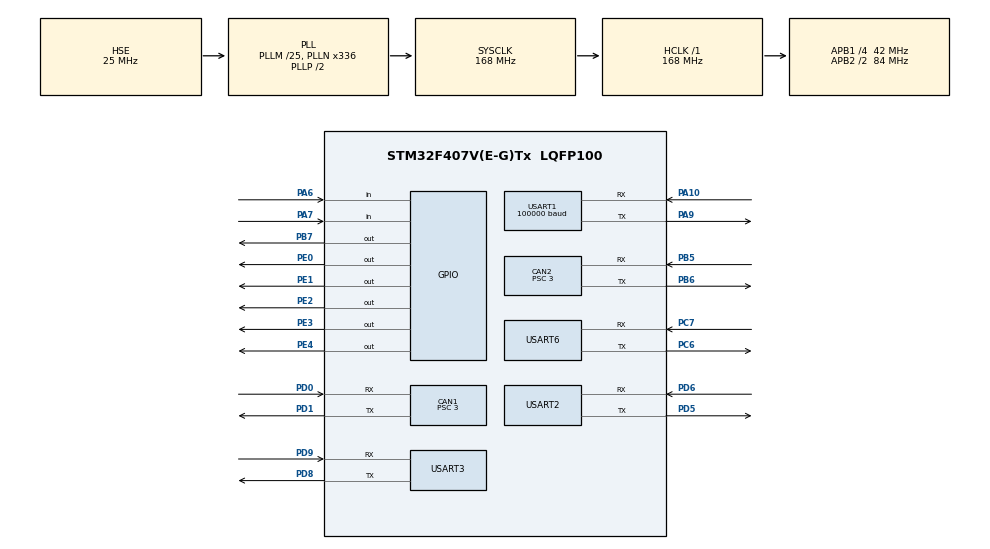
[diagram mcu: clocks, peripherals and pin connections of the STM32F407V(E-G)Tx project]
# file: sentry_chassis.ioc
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CAN1.BS1=CAN_BS1_8TQ
CAN1.BS2=CAN_BS2_5TQ
CAN1.CalculateBaudRate=1000000
CAN1.CalculateTimeBit=999.99
CAN1.CalculateTimeQuantum=71.42857142857143
CAN1.Prescaler=3
CAN2.BS1=CAN_BS1_8TQ
CAN2.BS2=CAN_BS2_5TQ
CAN2.CalculateBaudRate=1000000
CAN2.CalculateTimeBit=999.99
CAN2.CalculateTimeQuantum=71.42857142857143
CAN2.Prescaler=3
Dma.Request0=USART1_RX
Dma.Request1=USART3_RX
Dma.Request2=USART3_TX
Dma.Request3=USART6_RX
Dma.Request4=USART6_TX
Dma.Request5=USART2_RX
Dma.Request6=USART2_TX
Dma.USART1_RX.0.Direction=DMA_PERIPH_TO_MEMORY
Dma.USART1_RX.0.FIFOMode=DMA_FIFOMODE_DISABLE
Dma.USART1_RX.0.Instance=DMA2_Stream2
Dma.USART1_RX.0.MemDataAlignment=DMA_MDATAALIGN_BYTE
Dma.USART1_RX.0.MemInc=DMA_MINC_ENABLE
Dma.USART1_RX.0.Mode=DMA_CIRCULAR
Dma.USART1_RX.0.PeriphDataAlignment=DMA_PDATAALIGN_BYTE
Dma.USART1_RX.0.PeriphInc=DMA_PINC_DISABLE
Dma.USART1_RX.0.Priority=DMA_PRIORITY_VERY_HIGH
Dma.USART2_RX.5.Direction=DMA_PERIPH_TO_MEMORY
Dma.USART2_RX.5.FIFOMode=DMA_FIFOMODE_DISABLE
Dma.USART2_RX.5.Instance=DMA1_Stream5
Dma.USART2_RX.5.MemDataAlignment=DMA_MDATAALIGN_BYTE
Dma.USART2_RX.5.MemInc=DMA_MINC_ENABLE
Dma.USART2_RX.5.Mode=DMA_CIRCULAR
Dma.USART2_RX.5.PeriphDataAlignment=DMA_PDATAALIGN_BYTE
Dma.USART2_RX.5.PeriphInc=DMA_PINC_DISABLE
Dma.USART2_RX.5.Priority=DMA_PRIORITY_VERY_HIGH
Dma.USART2_TX.6.Direction=DMA_MEMORY_TO_PERIPH
Dma.USART2_TX.6.FIFOMode=DMA_FIFOMODE_DISABLE
Dma.USART2_TX.6.Instance=DMA1_Stream6
Dma.USART2_TX.6.MemDataAlignment=DMA_MDATAALIGN_BYTE
Dma.USART2_TX.6.MemInc=DMA_MINC_ENABLE
Dma.USART2_TX.6.Mode=DMA_NORMAL
Dma.USART2_TX.6.PeriphDataAlignment=DMA_PDATAALIGN_BYTE
Dma.USART2_TX.6.PeriphInc=DMA_PINC_DISABLE
Dma.USART2_TX.6.Priority=DMA_PRIORITY_VERY_HIGH
Dma.USART3_RX.1.Direction=DMA_PERIPH_TO_MEMORY
Dma.USART3_RX.1.FIFOMode=DMA_FIFOMODE_DISABLE
Dma.USART3_RX.1.Instance=DMA1_Stream1
Dma.USART3_RX.1.MemDataAlignment=DMA_MDATAALIGN_BYTE
Dma.USART3_RX.1.MemInc=DMA_MINC_ENABLE
Dma.USART3_RX.1.Mode=DMA_CIRCULAR
Dma.USART3_RX.1.PeriphDataAlignment=DMA_PDATAALIGN_BYTE
Dma.USART3_RX.1.PeriphInc=DMA_PINC_DISABLE
Dma.USART3_RX.1.Priority=DMA_PRIORITY_VERY_HIGH
Dma.USART3_TX.2.Direction=DMA_MEMORY_TO_PERIPH
Dma.USART3_TX.2.FIFOMode=DMA_FIFOMODE_DISABLE
Dma.USART3_TX.2.Instance=DMA1_Stream3
Dma.USART3_TX.2.MemDataAlignment=DMA_MDATAALIGN_BYTE
Dma.USART3_TX.2.MemInc=DMA_MINC_ENABLE
Dma.USART3_TX.2.Mode=DMA_CIRCULAR
Dma.USART3_TX.2.PeriphDataAlignment=DMA_PDATAALIGN_BYTE
Dma.USART3_TX.2.PeriphInc=DMA_PINC_DISABLE
Dma.USART3_TX.2.Priority=DMA_PRIORITY_VERY_HIGH
Dma.USART6_RX.3.Direction=DMA_PERIPH_TO_MEMORY
Dma.USART6_RX.3.FIFOMode=DMA_FIFOMODE_DISABLE
Dma.USART6_RX.3.Instance=DMA2_Stream1
Dma.USART6_RX.3.MemDataAlignment=DMA_MDATAALIGN_BYTE
Dma.USART6_RX.3.MemInc=DMA_MINC_ENABLE
Dma.USART6_RX.3.Mode=DMA_CIRCULAR
Dma.USART6_RX.3.PeriphDataAlignment=DMA_PDATAALIGN_BYTE
Dma.USART6_RX.3.PeriphInc=DMA_PINC_DISABLE
Dma.USART6_RX.3.Priority=DMA_PRIORITY_VERY_HIGH
Dma.USART6_TX.4.Direction=DMA_MEMORY_TO_PERIPH
Dma.USART6_TX.4.FIFOMode=DMA_FIFOMODE_DISABLE
Dma.USART6_TX.4.Instance=DMA2_Stream6
Dma.USART6_TX.4.MemDataAlignment=DMA_MDATAALIGN_BYTE
Dma.USART6_TX.4.MemInc=DMA_MINC_ENABLE
Dma.USART6_TX.4.Mode=DMA_CIRCULAR
Dma.USART6_TX.4.PeriphDataAlignment=DMA_PDATAALIGN_BYTE
Dma.USART6_TX.4.PeriphInc=DMA_PINC_DISABLE
Dma.USART6_TX.4.Priority=DMA_PRIORITY_VERY_HIGH
FREERTOS.MEMORY_ALLOCATION=2
FREERTOS.Tasks01=defaultTask,0,128,StartDefaultTask,Default,NULL,Dynamic,NULL,NULL;FireTask,1,128,Fire_Task,As external,NULL,Dynamic,NULL,NULL;DetectTASK,-1,128,Detect_TASK,As external,NULL,Dynamic,NULL,NULL;SAFETASK,2,128,SAFE_TASK,As external,NULL,Dynamic,NULL,NULL;LedTask,-3,128,Led_Task,As external,NULL,Dynamic,NULL,NULL
Mcu.Family=STM32F4
Mcu.Name=STM32F407V(E-G)Tx
Mcu.Package=LQFP100
NVIC.CAN1_RX0_IRQn=true\:5\:0\:false\:false\:true\:true\:true\:true
NVIC.CAN2_RX0_IRQn=true\:5\:0\:false\:false\:true\:true\:true\:true
NVIC.DMA1_Stream1_IRQn=true\:5\:0\:false\:false\:true\:true\:false\:true
NVIC.DMA1_Stream3_IRQn=true\:5\:0\:false\:false\:true\:true\:false\:true
NVIC.DMA1_Stream5_IRQn=true\:5\:0\:false\:false\:true\:true\:false\:true
NVIC.DMA1_Stream6_IRQn=true\:5\:0\:false\:false\:true\:true\:false\:true
NVIC.DMA2_Stream1_IRQn=true\:5\:0\:false\:false\:true\:true\:false\:true
NVIC.DMA2_Stream2_IRQn=true\:5\:0\:false\:false\:true\:true\:false\:true
NVIC.DMA2_Stream6_IRQn=true\:5\:0\:false\:false\:true\:true\:false\:true
NVIC.PriorityGroup=NVIC_PRIORITYGROUP_4
NVIC.TIM2_IRQn=true\:0\:0\:false\:false\:true\:false\:false\:true
NVIC.TimeBase=TIM2_IRQn
NVIC.TimeBaseIP=TIM2
NVIC.USART1_IRQn=true\:5\:0\:false\:false\:true\:true\:true\:true
NVIC.USART2_IRQn=true\:5\:0\:false\:false\:true\:true\:true\:true
NVIC.USART3_IRQn=true\:5\:0\:false\:false\:true\:true\:true\:true
NVIC.USART6_IRQn=true\:5\:0\:true\:false\:true\:true\:true\:true
PA10.Mode=Asynchronous
PA10.Signal=USART1_RX
PA13.Mode=Serial_Wire
PA13.Signal=SYS_JTMS-SWDIO
PA14.Mode=Serial_Wire
PA14.Signal=SYS_JTCK-SWCLK
PA6.GPIO_PuPd=GPIO_PULLDOWN
PA6.Signal=GPIO_Input
PA7.GPIO_PuPd=GPIO_PULLDOWN
PA7.Signal=GPIO_Input
PA9.Mode=Asynchronous
PA9.Signal=USART1_TX
PB5.Mode=CAN_Activate
PB5.Signal=CAN2_RX
PB6.Mode=CAN_Activate
PB6.Signal=CAN2_TX
PB7.GPIO_PuPd=GPIO_PULLUP
PB7.GPIO_Speed=GPIO_SPEED_FREQ_HIGH
PB7.PinState=GPIO_PIN_SET
PB7.Signal=GPIO_Output
PC6.Mode=Asynchronous
PC6.Signal=USART6_TX
PC7.Mode=Asynchronous
PC7.Signal=USART6_RX
PD0.Mode=CAN_Activate
PD0.Signal=CAN1_RX
PD1.Mode=CAN_Activate
PD1.Signal=CAN1_TX
PD5.Mode=Asynchronous
PD5.Signal=USART2_TX
PD6.Mode=Asynchronous
PD6.Signal=USART2_RX
PD8.Mode=Asynchronous
PD8.Signal=USART3_TX
PD9.Mode=Asynchronous
PD9.Signal=USART3_RX
PE0.GPIO_PuPd=GPIO_PULLUP
PE0.GPIO_Speed=GPIO_SPEED_FREQ_HIGH
PE0.PinState=GPIO_PIN_SET
PE0.Signal=GPIO_Output
PE1.GPIO_ModeDefaultOutputPP=GPIO_MODE_OUTPUT_PP
PE1.GPIO_PuPd=GPIO_PULLUP
PE1.GPIO_Speed=GPIO_SPEED_FREQ_HIGH
PE1.PinState=GPIO_PIN_SET
PE1.Signal=GPIO_Output
PE2.GPIO_ModeDefaultOutputPP=GPIO_MODE_OUTPUT_PP
PE2.GPIO_PuPd=GPIO_PULLUP
PE2.GPIO_Speed=GPIO_SPEED_FREQ_HIGH
PE2.PinState=GPIO_PIN_SET
PE2.Signal=GPIO_Output
PE3.GPIO_ModeDefaultOutputPP=GPIO_MODE_OUTPUT_PP
PE3.GPIO_PuPd=GPIO_PULLUP
PE3.GPIO_Speed=GPIO_SPEED_FREQ_HIGH
PE3.PinState=GPIO_PIN_SET
PE3.Signal=GPIO_Output
PE4.GPIO_ModeDefaultOutputPP=GPIO_MODE_OUTPUT_PP
PE4.GPIO_PuPd=GPIO_PULLUP
PE4.GPIO_Speed=GPIO_SPEED_FREQ_HIGH
PE4.PinState=GPIO_PIN_SET
PE4.Signal=GPIO_Output
PH0-OSC_IN.Mode=HSE-External-Oscillator
PH0-OSC_IN.Signal=RCC_OSC_IN
PH1-OSC_OUT.Mode=HSE-External-Oscillator
PH1-OSC_OUT.Signal=RCC_OSC_OUT
ProjectManager.HeapSize=0x200
ProjectManager.StackSize=0x400
ProjectManager.TargetToolchain=MDK-ARM V5.27
RCC.48MHZClocksFreq_Value=42000000
RCC.AHBFreq_Value=168000000
RCC.APB1CLKDivider=RCC_HCLK_DIV4
RCC.APB1Freq_Value=42000000
RCC.APB1TimFreq_Value=84000000
RCC.APB2CLKDivider=RCC_HCLK_DIV2
RCC.APB2Freq_Value=84000000
RCC.APB2TimFreq_Value=168000000
RCC.CortexFreq_Value=168000000
RCC.HCLKFreq_Value=168000000
RCC.HSE_VALUE=25000000
RCC.HSI_VALUE=16000000
RCC.LSE_VALUE=32768
RCC.PLLM=25
RCC.PLLN=336
RCC.PLLQ=8
RCC.PLLSourceVirtual=RCC_PLLSOURCE_HSE
RCC.SYSCLKFreq_VALUE=168000000
RCC.SYSCLKSource=RCC_SYSCLKSOURCE_PLLCLK
RCC.VCOOutputFreq_Value=336000000
USART1.BaudRate=100000
USART1.Parity=PARITY_EVEN
USART1.VirtualMode=VM_ASYNC
USART2.VirtualMode=VM_ASYNC
USART3.VirtualMode=VM_ASYNC
USART6.VirtualMode=VM_ASYNC
VP_FREERTOS_VS_CMSIS_V1.Mode=CMSIS_V1
VP_RNG_VS_RNG.Mode=RNG_Activate
VP_SYS_VS_tim2.Mode=TIM2
board=custom

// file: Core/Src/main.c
/* USER CODE BEGIN Header */
/**
  ******************************************************************************
  * @file           : main.c
  * @brief          : Main program body
  ******************************************************************************
  * @attention
  *
  * <h2><center>&copy; Copyright (c) 2021 STMicroelectronics.
  * All rights reserved.</center></h2>
  *
  * This software component is licensed by ST under Ultimate Liberty license
  * SLA0044, the "License"; You may not use this file except in compliance with
  * the License. You may obtain a copy of the License at:
  *                             www.st.com/SLA0044
  *
  ******************************************************************************
  */
/* USER CODE END Header */
#include "main.h"
#include "cmsis_os.h"
#include "can.h"
#include "dma.h"
#include "rng.h"
#include "usart.h"
#include "gpio.h"

/* USER CODE BEGIN Includes */
#include "SysInit.h"

/* USER CODE END Includes */

/* USER CODE BEGIN PTD */
extern CAN_HandleTypeDef hcan1;

/* USER CODE END PTD */

void SystemClock_Config(void);
void MX_FREERTOS_Init(void);

int main(void)
{

  /* MCU Configuration--------------------------------------------------------*/

  /* Reset of all peripherals, Initializes the Flash interface and the Systick. */
  HAL_Init();

  /* Configure the system clock */
  SystemClock_Config();

  /* Initialize all configured peripherals */
  MX_GPIO_Init();
  MX_DMA_Init();
  MX_CAN1_Init();
  MX_USART1_UART_Init();
  MX_USART3_UART_Init();
  MX_USART6_UART_Init();
  MX_USART2_UART_Init();
  MX_RNG_Init();
  MX_CAN2_Init();
  /* USER CODE BEGIN 2 */
	System_init();

  /* USER CODE END 2 */

  /* Call init function for freertos objects (in freertos.c) */
  MX_FREERTOS_Init();
  /* Start scheduler */
  osKernelStart();

  /* We should never get here as control is now taken by the scheduler */
  /* Infinite loop */
  while (1)
  {

  }
}

void SystemClock_Config(void)
{
  RCC_OscInitTypeDef RCC_OscInitStruct = {0};
  RCC_ClkInitTypeDef RCC_ClkInitStruct = {0};

  /** Configure the main internal regulator output voltage
  */
  __HAL_RCC_PWR_CLK_ENABLE();
  __HAL_PWR_VOLTAGESCALING_CONFIG(PWR_REGULATOR_VOLTAGE_SCALE1);
  /** Initializes the RCC Oscillators according to the specified parameters
  * in the RCC_OscInitTypeDef structure.
  */
  RCC_OscInitStruct.OscillatorType = RCC_OSCILLATORTYPE_HSE;
  RCC_OscInitStruct.HSEState = RCC_HSE_ON;
  RCC_OscInitStruct.PLL.PLLState = RCC_PLL_ON;
  RCC_OscInitStruct.PLL.PLLSource = RCC_PLLSOURCE_HSE;
  RCC_OscInitStruct.PLL.PLLM = 25;
  RCC_OscInitStruct.PLL.PLLN = 336;
  RCC_OscInitStruct.PLL.PLLP = RCC_PLLP_DIV2;
  RCC_OscInitStruct.PLL.PLLQ = 8;
  if (HAL_RCC_OscConfig(&RCC_OscInitStruct) != HAL_OK)
  {
    Error_Handler();
  }
  /** Initializes the CPU, AHB and APB buses clocks
  */
  RCC_ClkInitStruct.ClockType = RCC_CLOCKTYPE_HCLK|RCC_CLOCKTYPE_SYSCLK
                              |RCC_CLOCKTYPE_PCLK1|RCC_CLOCKTYPE_PCLK2;
  RCC_ClkInitStruct.SYSCLKSource = RCC_SYSCLKSOURCE_PLLCLK;
  RCC_ClkInitStruct.AHBCLKDivider = RCC_SYSCLK_DIV1;
  RCC_ClkInitStruct.APB1CLKDivider = RCC_HCLK_DIV4;
  RCC_ClkInitStruct.APB2CLKDivider = RCC_HCLK_DIV2;

  if (HAL_RCC_ClockConfig(&RCC_ClkInitStruct, FLASH_LATENCY_5) != HAL_OK)
  {
    Error_Handler();
  }
}

 /**
  * @brief  Period elapsed callback in non blocking mode
  * @note   This function is called  when TIM2 interrupt took place, inside
  * HAL_TIM_IRQHandler(). It makes a direct call to HAL_IncTick() to increment
  * a global variable "uwTick" used as application time base.
  * @param  htim : TIM handle
  * @retval None
  */
void HAL_TIM_PeriodElapsedCallback(TIM_HandleTypeDef *htim)
{
  if (htim->Instance == TIM2) {
    HAL_IncTick();
  }
}

void Error_Handler(void)
{
  __disable_irq();
  while (1)
  {
  }
}

/************************ (C) COPYRIGHT STMicroelectronics *****END OF FILE****/

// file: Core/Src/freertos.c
/* USER CODE BEGIN Header */
/**
  ******************************************************************************
  * File Name          : freertos.c
  * Description        : Code for freertos applications
  ******************************************************************************
  * @attention
  *
  * <h2><center>&copy; Copyright (c) 2021 STMicroelectronics.
  * All rights reserved.</center></h2>
  *
  * This software component is licensed by ST under Ultimate Liberty license
  * SLA0044, the "License"; You may not use this file except in compliance with
  * the License. You may obtain a copy of the License at:
  *                             www.st.com/SLA0044
  *
  ******************************************************************************
  */
/* USER CODE END Header */

#include "FreeRTOS.h"
#include "task.h"
#include "main.h"
#include "cmsis_os.h"

osThreadId defaultTaskHandle;
osThreadId FireTaskHandle;
osThreadId DetectTASKHandle;
osThreadId SAFETASKHandle;
osThreadId LedTaskHandle;

void StartDefaultTask(void const * argument);
extern void Fire_Task(void const * argument);
extern void Detect_TASK(void const * argument);
extern void SAFE_TASK(void const * argument);
extern void Led_Task(void const * argument);

void MX_FREERTOS_Init(void); /* (MISRA C 2004 rule 8.1) */

/* GetIdleTaskMemory prototype (linked to static allocation support) */
void vApplicationGetIdleTaskMemory( StaticTask_t **ppxIdleTaskTCBBuffer, StackType_t **ppxIdleTaskStackBuffer, uint32_t *pulIdleTaskStackSize );

/* USER CODE BEGIN GET_IDLE_TASK_MEMORY */
static StaticTask_t xIdleTaskTCBBuffer;
static StackType_t xIdleStack[configMINIMAL_STACK_SIZE];

void vApplicationGetIdleTaskMemory( StaticTask_t **ppxIdleTaskTCBBuffer, StackType_t **ppxIdleTaskStackBuffer, uint32_t *pulIdleTaskStackSize )
{
  *ppxIdleTaskTCBBuffer = &xIdleTaskTCBBuffer;
  *ppxIdleTaskStackBuffer = &xIdleStack[0];
  *pulIdleTaskStackSize = configMINIMAL_STACK_SIZE;
  /* place for user code */
}
/* USER CODE END GET_IDLE_TASK_MEMORY */

void MX_FREERTOS_Init(void) {

  /* Create the thread(s) */
  /* definition and creation of defaultTask */
  osThreadDef(defaultTask, StartDefaultTask, osPriorityNormal, 0, 128);
  defaultTaskHandle = osThreadCreate(osThread(defaultTask), NULL);

  /* definition and creation of FireTask */
  osThreadDef(FireTask, Fire_Task, osPriorityAboveNormal, 0, 128);
  FireTaskHandle = osThreadCreate(osThread(FireTask), NULL);

  /* definition and creation of DetectTASK */
  osThreadDef(DetectTASK, Detect_TASK, osPriorityBelowNormal, 0, 128);
  DetectTASKHandle = osThreadCreate(osThread(DetectTASK), NULL);

  /* definition and creation of SAFETASK */
  osThreadDef(SAFETASK, SAFE_TASK, osPriorityHigh, 0, 128);
  SAFETASKHandle = osThreadCreate(osThread(SAFETASK), NULL);

  /* definition and creation of LedTask */
  osThreadDef(LedTask, Led_Task, osPriorityIdle, 0, 128);
  LedTaskHandle = osThreadCreate(osThread(LedTask), NULL);

}

void StartDefaultTask(void const * argument)
{
  for(;;)
  {
    osDelay(1);
  }
}

/************************ (C) COPYRIGHT STMicroelectronics *****END OF FILE****/
